AUTOSAR XML (schema 00051)
package /Runnables_Lab1
  sender receiver interface SRI_ThrottleCmd
    data ThrottleCmd: type=uint32
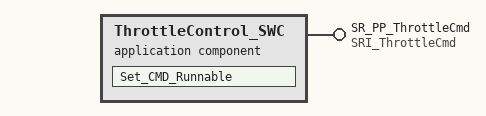
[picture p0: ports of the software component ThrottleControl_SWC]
  application sw component type ThrottleControl_SWC
    provide port SR_PP_ThrottleCmd: provided-interface=SRI_ThrottleCmd
    behavior ThrottleControl_Behavior
      runnable Set_CMD_Runnable: symbol=Set_CMD
        data-write-access:
          access CMD_Data: accessed-variable=SR_PP_ThrottleCmd.ThrottleCmd
